VERSION ""

NS_ :

BS_:

BU_: BMS

BO_ 2147528816 SEG_1_MSG: 8 BMS
 SG_ SEG_1_isFaultDetected : 49|1@1+ (1,0) [0|0] "" Vector__XXX
 SG_ SEG_1_isCommsError : 48|1@1+ (1,0) [0|0] "" Vector__XXX
 SG_ SEG_1_IC_Temp : 32|16@1- (0.01,0) [0|0] "degC" Vector__XXX
 SG_ SEG_1_IC_Voltage : 0|32@1- (0.001,0) [0|0] "V" Vector__XXX

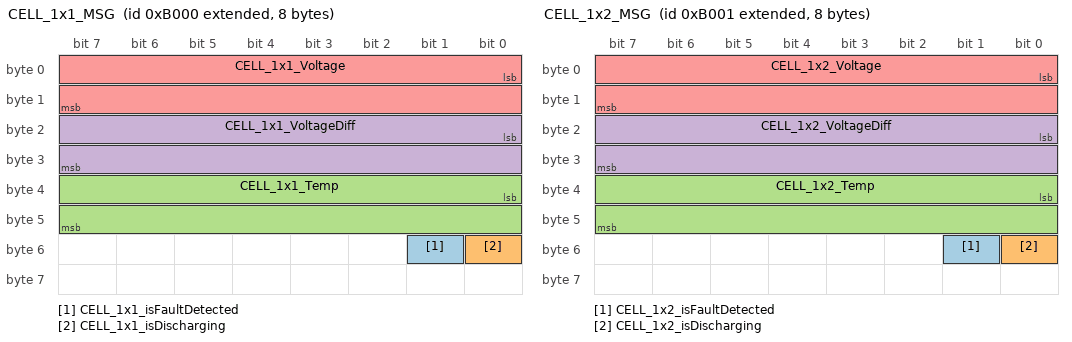
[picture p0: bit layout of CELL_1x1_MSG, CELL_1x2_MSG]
BO_ 2147528704 CELL_1x1_MSG: 8 BMS
 SG_ CELL_1x1_isFaultDetected : 49|1@1+ (1,0) [0|0] "" Vector__XXX
 SG_ CELL_1x1_isDischarging : 48|1@1+ (1,0) [0|0] "" Vector__XXX
 SG_ CELL_1x1_Temp : 32|16@1- (0.01,0) [0|0] "degC" Vector__XXX
 SG_ CELL_1x1_VoltageDiff : 16|16@1- (1,0) [0|0] "mV" Vector__XXX
 SG_ CELL_1x1_Voltage : 0|16@1- (0.001,0) [0|0] "V" Vector__XXX

BO_ 2147528705 CELL_1x2_MSG: 8 BMS
 SG_ CELL_1x2_isFaultDetected : 49|1@1+ (1,0) [0|0] "" Vector__XXX
 SG_ CELL_1x2_isDischarging : 48|1@1+ (1,0) [0|0] "" Vector__XXX
 SG_ CELL_1x2_Temp : 32|16@1- (0.01,0) [0|0] "degC" Vector__XXX
 SG_ CELL_1x2_VoltageDiff : 16|16@1- (1,0) [0|0] "mV" Vector__XXX
 SG_ CELL_1x2_Voltage : 0|16@1- (0.001,0) [0|0] "V" Vector__XXX

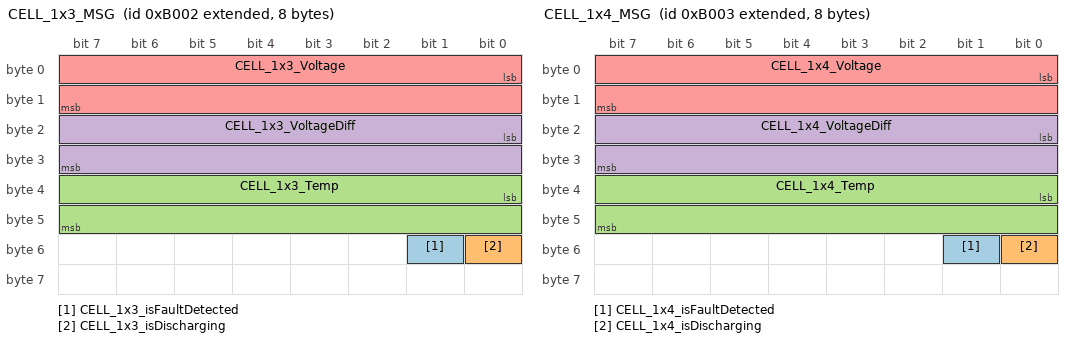
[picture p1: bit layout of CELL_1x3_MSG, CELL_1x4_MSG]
BO_ 2147528706 CELL_1x3_MSG: 8 BMS
 SG_ CELL_1x3_isFaultDetected : 49|1@1+ (1,0) [0|0] "" Vector__XXX
 SG_ CELL_1x3_isDischarging : 48|1@1+ (1,0) [0|0] "" Vector__XXX
 SG_ CELL_1x3_Temp : 32|16@1- (0.01,0) [0|0] "degC" Vector__XXX
 SG_ CELL_1x3_VoltageDiff : 16|16@1- (1,0) [0|0] "mV" Vector__XXX
 SG_ CELL_1x3_Voltage : 0|16@1- (0.001,0) [0|0] "V" Vector__XXX

BO_ 2147528707 CELL_1x4_MSG: 8 BMS
 SG_ CELL_1x4_isFaultDetected : 49|1@1+ (1,0) [0|0] "" Vector__XXX
 SG_ CELL_1x4_isDischarging : 48|1@1+ (1,0) [0|0] "" Vector__XXX
 SG_ CELL_1x4_Temp : 32|16@1- (0.01,0) [0|0] "degC" Vector__XXX
 SG_ CELL_1x4_VoltageDiff : 16|16@1- (1,0) [0|0] "mV" Vector__XXX
 SG_ CELL_1x4_Voltage : 0|16@1- (0.001,0) [0|0] "V" Vector__XXX

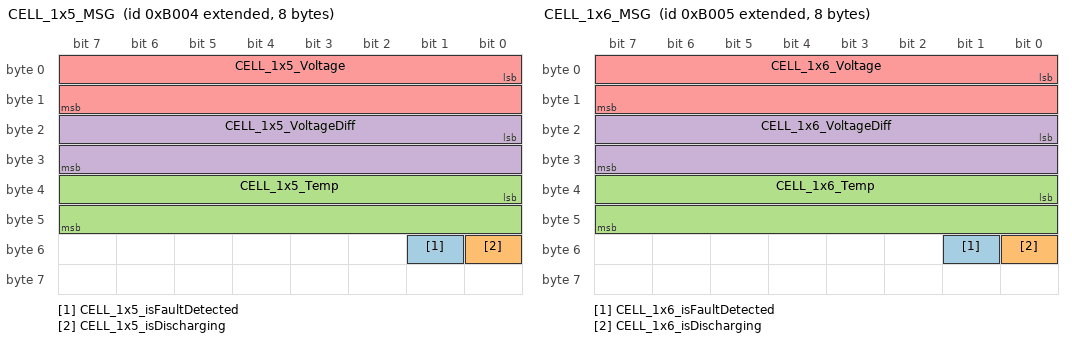
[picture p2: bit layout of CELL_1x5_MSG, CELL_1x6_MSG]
BO_ 2147528708 CELL_1x5_MSG: 8 BMS
 SG_ CELL_1x5_isFaultDetected : 49|1@1+ (1,0) [0|0] "" Vector__XXX
 SG_ CELL_1x5_isDischarging : 48|1@1+ (1,0) [0|0] "" Vector__XXX
 SG_ CELL_1x5_Temp : 32|16@1- (0.01,0) [0|0] "degC" Vector__XXX
 SG_ CELL_1x5_VoltageDiff : 16|16@1- (1,0) [0|0] "mV" Vector__XXX
 SG_ CELL_1x5_Voltage : 0|16@1- (0.001,0) [0|0] "V" Vector__XXX

BO_ 2147528709 CELL_1x6_MSG: 8 BMS
 SG_ CELL_1x6_isFaultDetected : 49|1@1+ (1,0) [0|0] "" Vector__XXX
 SG_ CELL_1x6_isDischarging : 48|1@1+ (1,0) [0|0] "" Vector__XXX
 SG_ CELL_1x6_Temp : 32|16@1- (0.01,0) [0|0] "degC" Vector__XXX
 SG_ CELL_1x6_VoltageDiff : 16|16@1- (1,0) [0|0] "mV" Vector__XXX
 SG_ CELL_1x6_Voltage : 0|16@1- (0.001,0) [0|0] "V" Vector__XXX

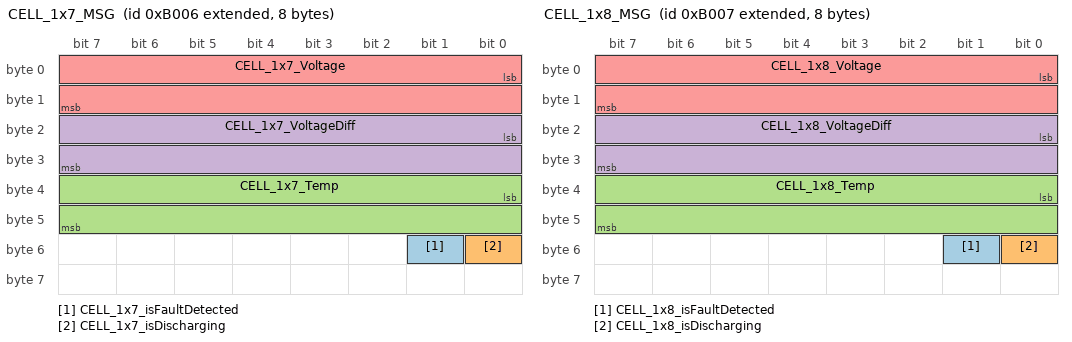
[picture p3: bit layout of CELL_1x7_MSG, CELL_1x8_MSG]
BO_ 2147528710 CELL_1x7_MSG: 8 BMS
 SG_ CELL_1x7_isFaultDetected : 49|1@1+ (1,0) [0|0] "" Vector__XXX
 SG_ CELL_1x7_isDischarging : 48|1@1+ (1,0) [0|0] "" Vector__XXX
 SG_ CELL_1x7_Temp : 32|16@1- (0.01,0) [0|0] "degC" Vector__XXX
 SG_ CELL_1x7_VoltageDiff : 16|16@1- (1,0) [0|0] "mV" Vector__XXX
 SG_ CELL_1x7_Voltage : 0|16@1- (0.001,0) [0|0] "V" Vector__XXX

BO_ 2147528711 CELL_1x8_MSG: 8 BMS
 SG_ CELL_1x8_isFaultDetected : 49|1@1+ (1,0) [0|0] "" Vector__XXX
 SG_ CELL_1x8_isDischarging : 48|1@1+ (1,0) [0|0] "" Vector__XXX
 SG_ CELL_1x8_Temp : 32|16@1- (0.01,0) [0|0] "degC" Vector__XXX
 SG_ CELL_1x8_VoltageDiff : 16|16@1- (1,0) [0|0] "mV" Vector__XXX
 SG_ CELL_1x8_Voltage : 0|16@1- (0.001,0) [0|0] "V" Vector__XXX

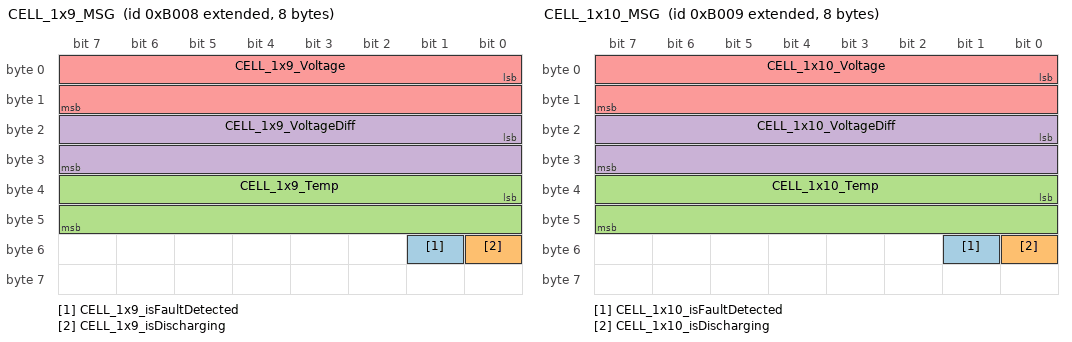
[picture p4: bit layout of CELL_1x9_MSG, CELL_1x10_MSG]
BO_ 2147528712 CELL_1x9_MSG: 8 BMS
 SG_ CELL_1x9_isFaultDetected : 49|1@1+ (1,0) [0|0] "" Vector__XXX
 SG_ CELL_1x9_isDischarging : 48|1@1+ (1,0) [0|0] "" Vector__XXX
 SG_ CELL_1x9_Temp : 32|16@1- (0.01,0) [0|0] "degC" Vector__XXX
 SG_ CELL_1x9_VoltageDiff : 16|16@1- (1,0) [0|0] "mV" Vector__XXX
 SG_ CELL_1x9_Voltage : 0|16@1- (0.001,0) [0|0] "V" Vector__XXX

BO_ 2147528713 CELL_1x10_MSG: 8 BMS
 SG_ CELL_1x10_isFaultDetected : 49|1@1+ (1,0) [0|0] "" Vector__XXX
 SG_ CELL_1x10_isDischarging : 48|1@1+ (1,0) [0|0] "" Vector__XXX
 SG_ CELL_1x10_Temp : 32|16@1- (0.01,0) [0|0] "degC" Vector__XXX
 SG_ CELL_1x10_VoltageDiff : 16|16@1- (1,0) [0|0] "mV" Vector__XXX
 SG_ CELL_1x10_Voltage : 0|16@1- (0.001,0) [0|0] "V" Vector__XXX

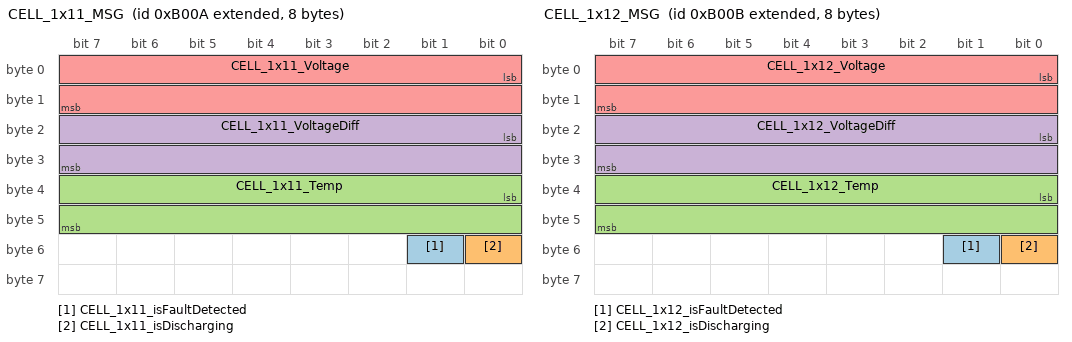
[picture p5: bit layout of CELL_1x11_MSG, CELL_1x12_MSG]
BO_ 2147528714 CELL_1x11_MSG: 8 BMS
 SG_ CELL_1x11_isFaultDetected : 49|1@1+ (1,0) [0|0] "" Vector__XXX
 SG_ CELL_1x11_isDischarging : 48|1@1+ (1,0) [0|0] "" Vector__XXX
 SG_ CELL_1x11_Temp : 32|16@1- (0.01,0) [0|0] "degC" Vector__XXX
 SG_ CELL_1x11_VoltageDiff : 16|16@1- (1,0) [0|0] "mV" Vector__XXX
 SG_ CELL_1x11_Voltage : 0|16@1- (0.001,0) [0|0] "V" Vector__XXX

BO_ 2147528715 CELL_1x12_MSG: 8 BMS
 SG_ CELL_1x12_isFaultDetected : 49|1@1+ (1,0) [0|0] "" Vector__XXX
 SG_ CELL_1x12_isDischarging : 48|1@1+ (1,0) [0|0] "" Vector__XXX
 SG_ CELL_1x12_Temp : 32|16@1- (0.01,0) [0|0] "degC" Vector__XXX
 SG_ CELL_1x12_VoltageDiff : 16|16@1- (1,0) [0|0] "mV" Vector__XXX
 SG_ CELL_1x12_Voltage : 0|16@1- (0.001,0) [0|0] "V" Vector__XXX

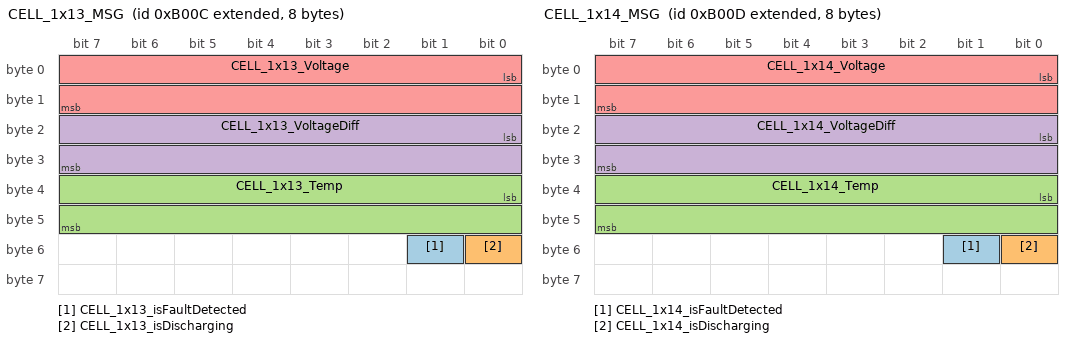
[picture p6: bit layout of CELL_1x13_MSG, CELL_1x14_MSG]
BO_ 2147528716 CELL_1x13_MSG: 8 BMS
 SG_ CELL_1x13_isFaultDetected : 49|1@1+ (1,0) [0|0] "" Vector__XXX
 SG_ CELL_1x13_isDischarging : 48|1@1+ (1,0) [0|0] "" Vector__XXX
 SG_ CELL_1x13_Temp : 32|16@1- (0.01,0) [0|0] "degC" Vector__XXX
 SG_ CELL_1x13_VoltageDiff : 16|16@1- (1,0) [0|0] "mV" Vector__XXX
 SG_ CELL_1x13_Voltage : 0|16@1- (0.001,0) [0|0] "V" Vector__XXX

BO_ 2147528717 CELL_1x14_MSG: 8 BMS
 SG_ CELL_1x14_isFaultDetected : 49|1@1+ (1,0) [0|0] "" Vector__XXX
 SG_ CELL_1x14_isDischarging : 48|1@1+ (1,0) [0|0] "" Vector__XXX
 SG_ CELL_1x14_Temp : 32|16@1- (0.01,0) [0|0] "degC" Vector__XXX
 SG_ CELL_1x14_VoltageDiff : 16|16@1- (1,0) [0|0] "mV" Vector__XXX
 SG_ CELL_1x14_Voltage : 0|16@1- (0.001,0) [0|0] "V" Vector__XXX

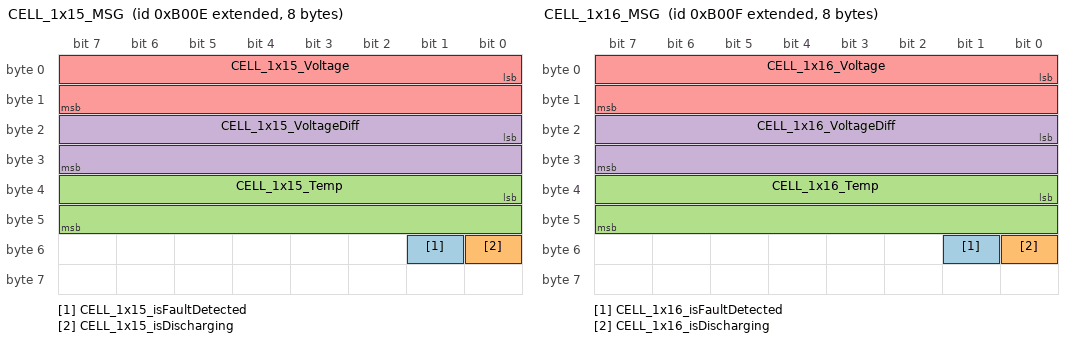
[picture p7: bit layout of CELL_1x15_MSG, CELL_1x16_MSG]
BO_ 2147528718 CELL_1x15_MSG: 8 BMS
 SG_ CELL_1x15_isFaultDetected : 49|1@1+ (1,0) [0|0] "" Vector__XXX
 SG_ CELL_1x15_isDischarging : 48|1@1+ (1,0) [0|0] "" Vector__XXX
 SG_ CELL_1x15_Temp : 32|16@1- (0.01,0) [0|0] "degC" Vector__XXX
 SG_ CELL_1x15_VoltageDiff : 16|16@1- (1,0) [0|0] "mV" Vector__XXX
 SG_ CELL_1x15_Voltage : 0|16@1- (0.001,0) [0|0] "V" Vector__XXX

BO_ 2147528719 CELL_1x16_MSG: 8 BMS
 SG_ CELL_1x16_isFaultDetected : 49|1@1+ (1,0) [0|0] "" Vector__XXX
 SG_ CELL_1x16_isDischarging : 48|1@1+ (1,0) [0|0] "" Vector__XXX
 SG_ CELL_1x16_Temp : 32|16@1- (0.01,0) [0|0] "degC" Vector__XXX
 SG_ CELL_1x16_VoltageDiff : 16|16@1- (1,0) [0|0] "mV" Vector__XXX
 SG_ CELL_1x16_Voltage : 0|16@1- (0.001,0) [0|0] "V" Vector__XXX

BO_ 2147528817 SEG_2_MSG: 8 BMS
 SG_ SEG_2_isFaultDetected : 49|1@1+ (1,0) [0|0] "" Vector__XXX
 SG_ SEG_2_isCommsError : 48|1@1+ (1,0) [0|0] "" Vector__XXX
 SG_ SEG_2_IC_Temp : 32|16@1- (0.01,0) [0|0] "degC" Vector__XXX
 SG_ SEG_2_IC_Voltage : 0|32@1- (0.001,0) [0|0] "V" Vector__XXX

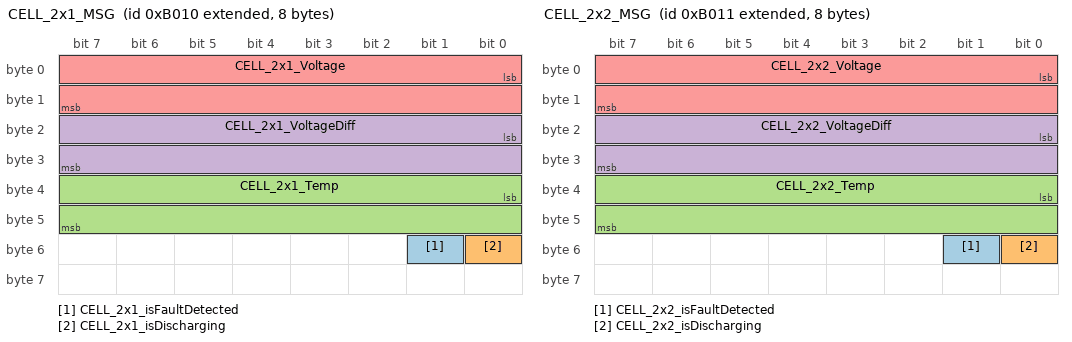
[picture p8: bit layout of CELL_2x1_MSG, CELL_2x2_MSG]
BO_ 2147528720 CELL_2x1_MSG: 8 BMS
 SG_ CELL_2x1_isFaultDetected : 49|1@1+ (1,0) [0|0] "" Vector__XXX
 SG_ CELL_2x1_isDischarging : 48|1@1+ (1,0) [0|0] "" Vector__XXX
 SG_ CELL_2x1_Temp : 32|16@1- (0.01,0) [0|0] "degC" Vector__XXX
 SG_ CELL_2x1_VoltageDiff : 16|16@1- (1,0) [0|0] "mV" Vector__XXX
 SG_ CELL_2x1_Voltage : 0|16@1- (0.001,0) [0|0] "V" Vector__XXX

BO_ 2147528721 CELL_2x2_MSG: 8 BMS
 SG_ CELL_2x2_isFaultDetected : 49|1@1+ (1,0) [0|0] "" Vector__XXX
 SG_ CELL_2x2_isDischarging : 48|1@1+ (1,0) [0|0] "" Vector__XXX
 SG_ CELL_2x2_Temp : 32|16@1- (0.01,0) [0|0] "degC" Vector__XXX
 SG_ CELL_2x2_VoltageDiff : 16|16@1- (1,0) [0|0] "mV" Vector__XXX
 SG_ CELL_2x2_Voltage : 0|16@1- (0.001,0) [0|0] "V" Vector__XXX

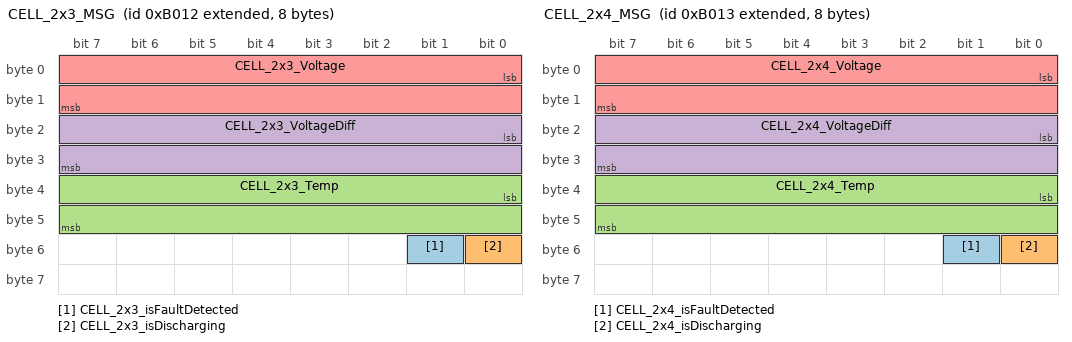
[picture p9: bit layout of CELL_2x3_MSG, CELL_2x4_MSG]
BO_ 2147528722 CELL_2x3_MSG: 8 BMS
 SG_ CELL_2x3_isFaultDetected : 49|1@1+ (1,0) [0|0] "" Vector__XXX
 SG_ CELL_2x3_isDischarging : 48|1@1+ (1,0) [0|0] "" Vector__XXX
 SG_ CELL_2x3_Temp : 32|16@1- (0.01,0) [0|0] "degC" Vector__XXX
 SG_ CELL_2x3_VoltageDiff : 16|16@1- (1,0) [0|0] "mV" Vector__XXX
 SG_ CELL_2x3_Voltage : 0|16@1- (0.001,0) [0|0] "V" Vector__XXX

BO_ 2147528723 CELL_2x4_MSG: 8 BMS
 SG_ CELL_2x4_isFaultDetected : 49|1@1+ (1,0) [0|0] "" Vector__XXX
 SG_ CELL_2x4_isDischarging : 48|1@1+ (1,0) [0|0] "" Vector__XXX
 SG_ CELL_2x4_Temp : 32|16@1- (0.01,0) [0|0] "degC" Vector__XXX
 SG_ CELL_2x4_VoltageDiff : 16|16@1- (1,0) [0|0] "mV" Vector__XXX
 SG_ CELL_2x4_Voltage : 0|16@1- (0.001,0) [0|0] "V" Vector__XXX

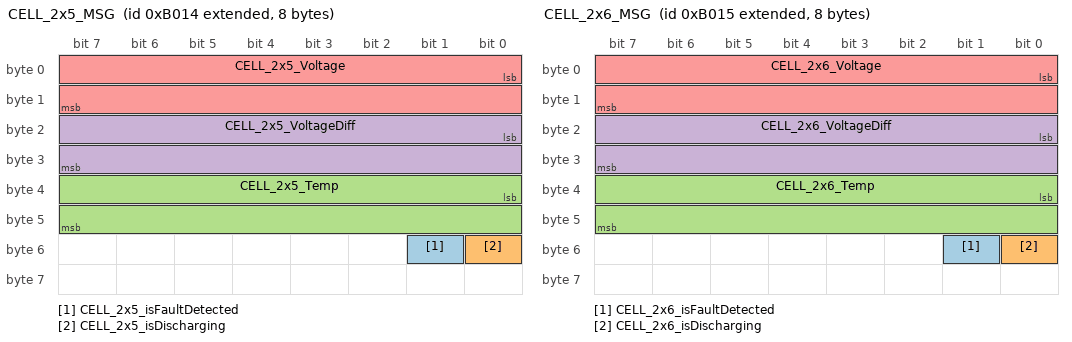
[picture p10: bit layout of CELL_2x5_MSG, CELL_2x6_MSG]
BO_ 2147528724 CELL_2x5_MSG: 8 BMS
 SG_ CELL_2x5_isFaultDetected : 49|1@1+ (1,0) [0|0] "" Vector__XXX
 SG_ CELL_2x5_isDischarging : 48|1@1+ (1,0) [0|0] "" Vector__XXX
 SG_ CELL_2x5_Temp : 32|16@1- (0.01,0) [0|0] "degC" Vector__XXX
 SG_ CELL_2x5_VoltageDiff : 16|16@1- (1,0) [0|0] "mV" Vector__XXX
 SG_ CELL_2x5_Voltage : 0|16@1- (0.001,0) [0|0] "V" Vector__XXX

BO_ 2147528725 CELL_2x6_MSG: 8 BMS
 SG_ CELL_2x6_isFaultDetected : 49|1@1+ (1,0) [0|0] "" Vector__XXX
 SG_ CELL_2x6_isDischarging : 48|1@1+ (1,0) [0|0] "" Vector__XXX
 SG_ CELL_2x6_Temp : 32|16@1- (0.01,0) [0|0] "degC" Vector__XXX
 SG_ CELL_2x6_VoltageDiff : 16|16@1- (1,0) [0|0] "mV" Vector__XXX
 SG_ CELL_2x6_Voltage : 0|16@1- (0.001,0) [0|0] "V" Vector__XXX

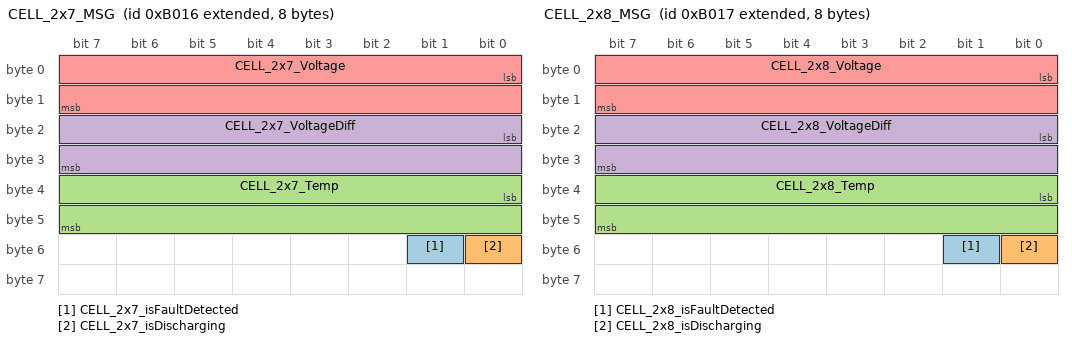
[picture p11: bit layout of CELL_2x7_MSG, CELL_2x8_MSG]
BO_ 2147528726 CELL_2x7_MSG: 8 BMS
 SG_ CELL_2x7_isFaultDetected : 49|1@1+ (1,0) [0|0] "" Vector__XXX
 SG_ CELL_2x7_isDischarging : 48|1@1+ (1,0) [0|0] "" Vector__XXX
 SG_ CELL_2x7_Temp : 32|16@1- (0.01,0) [0|0] "degC" Vector__XXX
 SG_ CELL_2x7_VoltageDiff : 16|16@1- (1,0) [0|0] "mV" Vector__XXX
 SG_ CELL_2x7_Voltage : 0|16@1- (0.001,0) [0|0] "V" Vector__XXX

BO_ 2147528727 CELL_2x8_MSG: 8 BMS
 SG_ CELL_2x8_isFaultDetected : 49|1@1+ (1,0) [0|0] "" Vector__XXX
 SG_ CELL_2x8_isDischarging : 48|1@1+ (1,0) [0|0] "" Vector__XXX
 SG_ CELL_2x8_Temp : 32|16@1- (0.01,0) [0|0] "degC" Vector__XXX
 SG_ CELL_2x8_VoltageDiff : 16|16@1- (1,0) [0|0] "mV" Vector__XXX
 SG_ CELL_2x8_Voltage : 0|16@1- (0.001,0) [0|0] "V" Vector__XXX

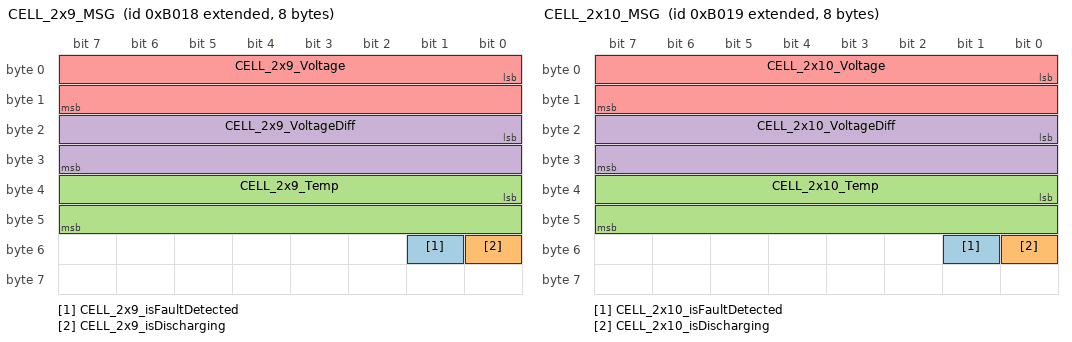
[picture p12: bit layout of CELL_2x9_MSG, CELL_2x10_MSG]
BO_ 2147528728 CELL_2x9_MSG: 8 BMS
 SG_ CELL_2x9_isFaultDetected : 49|1@1+ (1,0) [0|0] "" Vector__XXX
 SG_ CELL_2x9_isDischarging : 48|1@1+ (1,0) [0|0] "" Vector__XXX
 SG_ CELL_2x9_Temp : 32|16@1- (0.01,0) [0|0] "degC" Vector__XXX
 SG_ CELL_2x9_VoltageDiff : 16|16@1- (1,0) [0|0] "mV" Vector__XXX
 SG_ CELL_2x9_Voltage : 0|16@1- (0.001,0) [0|0] "V" Vector__XXX

BO_ 2147528729 CELL_2x10_MSG: 8 BMS
 SG_ CELL_2x10_isFaultDetected : 49|1@1+ (1,0) [0|0] "" Vector__XXX
 SG_ CELL_2x10_isDischarging : 48|1@1+ (1,0) [0|0] "" Vector__XXX
 SG_ CELL_2x10_Temp : 32|16@1- (0.01,0) [0|0] "degC" Vector__XXX
 SG_ CELL_2x10_VoltageDiff : 16|16@1- (1,0) [0|0] "mV" Vector__XXX
 SG_ CELL_2x10_Voltage : 0|16@1- (0.001,0) [0|0] "V" Vector__XXX

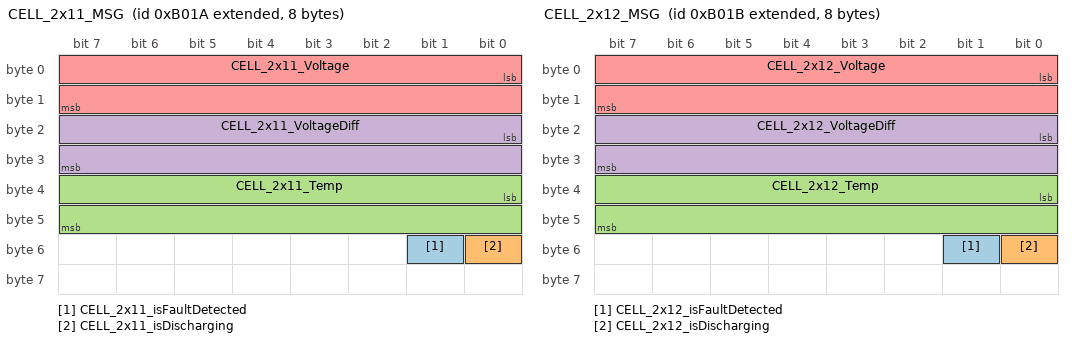
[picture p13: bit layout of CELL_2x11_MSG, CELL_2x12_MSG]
BO_ 2147528730 CELL_2x11_MSG: 8 BMS
 SG_ CELL_2x11_isFaultDetected : 49|1@1+ (1,0) [0|0] "" Vector__XXX
 SG_ CELL_2x11_isDischarging : 48|1@1+ (1,0) [0|0] "" Vector__XXX
 SG_ CELL_2x11_Temp : 32|16@1- (0.01,0) [0|0] "degC" Vector__XXX
 SG_ CELL_2x11_VoltageDiff : 16|16@1- (1,0) [0|0] "mV" Vector__XXX
 SG_ CELL_2x11_Voltage : 0|16@1- (0.001,0) [0|0] "V" Vector__XXX

BO_ 2147528731 CELL_2x12_MSG: 8 BMS
 SG_ CELL_2x12_isFaultDetected : 49|1@1+ (1,0) [0|0] "" Vector__XXX
 SG_ CELL_2x12_isDischarging : 48|1@1+ (1,0) [0|0] "" Vector__XXX
 SG_ CELL_2x12_Temp : 32|16@1- (0.01,0) [0|0] "degC" Vector__XXX
 SG_ CELL_2x12_VoltageDiff : 16|16@1- (1,0) [0|0] "mV" Vector__XXX
 SG_ CELL_2x12_Voltage : 0|16@1- (0.001,0) [0|0] "V" Vector__XXX

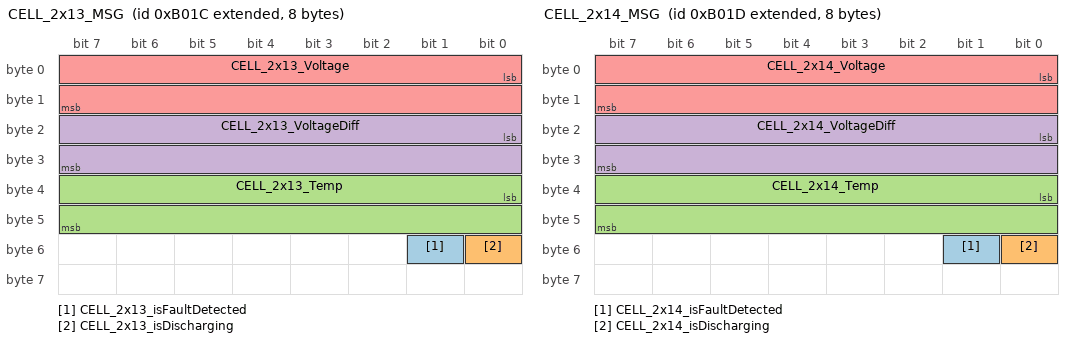
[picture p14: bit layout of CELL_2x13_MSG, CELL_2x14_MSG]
BO_ 2147528732 CELL_2x13_MSG: 8 BMS
 SG_ CELL_2x13_isFaultDetected : 49|1@1+ (1,0) [0|0] "" Vector__XXX
 SG_ CELL_2x13_isDischarging : 48|1@1+ (1,0) [0|0] "" Vector__XXX
 SG_ CELL_2x13_Temp : 32|16@1- (0.01,0) [0|0] "degC" Vector__XXX
 SG_ CELL_2x13_VoltageDiff : 16|16@1- (1,0) [0|0] "mV" Vector__XXX
 SG_ CELL_2x13_Voltage : 0|16@1- (0.001,0) [0|0] "V" Vector__XXX

BO_ 2147528733 CELL_2x14_MSG: 8 BMS
 SG_ CELL_2x14_isFaultDetected : 49|1@1+ (1,0) [0|0] "" Vector__XXX
 SG_ CELL_2x14_isDischarging : 48|1@1+ (1,0) [0|0] "" Vector__XXX
 SG_ CELL_2x14_Temp : 32|16@1- (0.01,0) [0|0] "degC" Vector__XXX
 SG_ CELL_2x14_VoltageDiff : 16|16@1- (1,0) [0|0] "mV" Vector__XXX
 SG_ CELL_2x14_Voltage : 0|16@1- (0.001,0) [0|0] "V" Vector__XXX

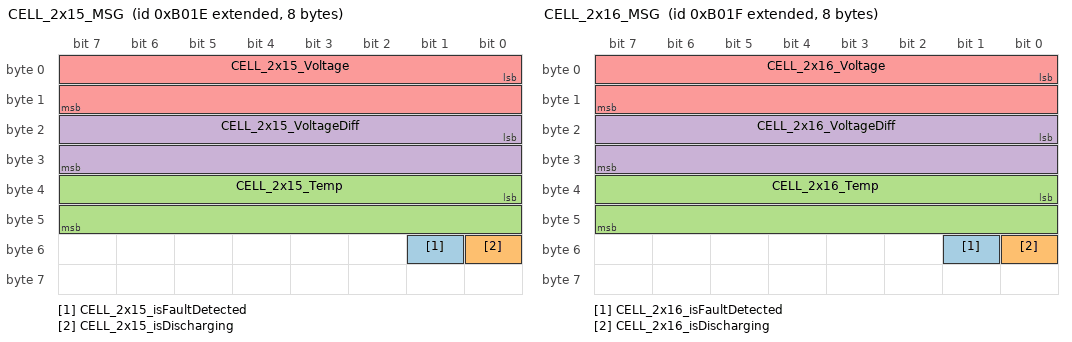
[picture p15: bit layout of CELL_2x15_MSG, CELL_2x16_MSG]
BO_ 2147528734 CELL_2x15_MSG: 8 BMS
 SG_ CELL_2x15_isFaultDetected : 49|1@1+ (1,0) [0|0] "" Vector__XXX
 SG_ CELL_2x15_isDischarging : 48|1@1+ (1,0) [0|0] "" Vector__XXX
 SG_ CELL_2x15_Temp : 32|16@1- (0.01,0) [0|0] "degC" Vector__XXX
 SG_ CELL_2x15_VoltageDiff : 16|16@1- (1,0) [0|0] "mV" Vector__XXX
 SG_ CELL_2x15_Voltage : 0|16@1- (0.001,0) [0|0] "V" Vector__XXX

BO_ 2147528735 CELL_2x16_MSG: 8 BMS
 SG_ CELL_2x16_isFaultDetected : 49|1@1+ (1,0) [0|0] "" Vector__XXX
 SG_ CELL_2x16_isDischarging : 48|1@1+ (1,0) [0|0] "" Vector__XXX
 SG_ CELL_2x16_Temp : 32|16@1- (0.01,0) [0|0] "degC" Vector__XXX
 SG_ CELL_2x16_VoltageDiff : 16|16@1- (1,0) [0|0] "mV" Vector__XXX
 SG_ CELL_2x16_Voltage : 0|16@1- (0.001,0) [0|0] "V" Vector__XXX

BO_ 2147528818 SEG_3_MSG: 8 BMS
 SG_ SEG_3_isFaultDetected : 49|1@1+ (1,0) [0|0] "" Vector__XXX
 SG_ SEG_3_isCommsError : 48|1@1+ (1,0) [0|0] "" Vector__XXX
 SG_ SEG_3_IC_Temp : 32|16@1- (0.01,0) [0|0] "degC" Vector__XXX
 SG_ SEG_3_IC_Voltage : 0|32@1- (0.001,0) [0|0] "V" Vector__XXX

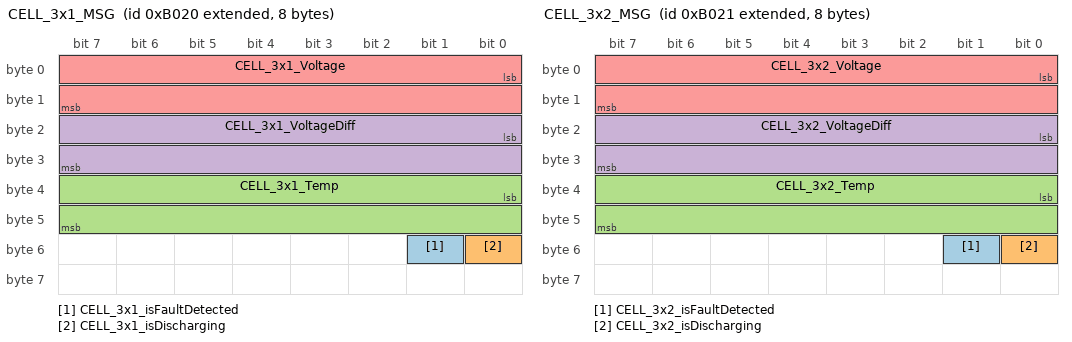
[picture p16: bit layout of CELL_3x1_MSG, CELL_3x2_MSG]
BO_ 2147528736 CELL_3x1_MSG: 8 BMS
 SG_ CELL_3x1_isFaultDetected : 49|1@1+ (1,0) [0|0] "" Vector__XXX
 SG_ CELL_3x1_isDischarging : 48|1@1+ (1,0) [0|0] "" Vector__XXX
 SG_ CELL_3x1_Temp : 32|16@1- (0.01,0) [0|0] "degC" Vector__XXX
 SG_ CELL_3x1_VoltageDiff : 16|16@1- (1,0) [0|0] "mV" Vector__XXX
 SG_ CELL_3x1_Voltage : 0|16@1- (0.001,0) [0|0] "V" Vector__XXX

BO_ 2147528737 CELL_3x2_MSG: 8 BMS
 SG_ CELL_3x2_isFaultDetected : 49|1@1+ (1,0) [0|0] "" Vector__XXX
 SG_ CELL_3x2_isDischarging : 48|1@1+ (1,0) [0|0] "" Vector__XXX
 SG_ CELL_3x2_Temp : 32|16@1- (0.01,0) [0|0] "degC" Vector__XXX
 SG_ CELL_3x2_VoltageDiff : 16|16@1- (1,0) [0|0] "mV" Vector__XXX
 SG_ CELL_3x2_Voltage : 0|16@1- (0.001,0) [0|0] "V" Vector__XXX

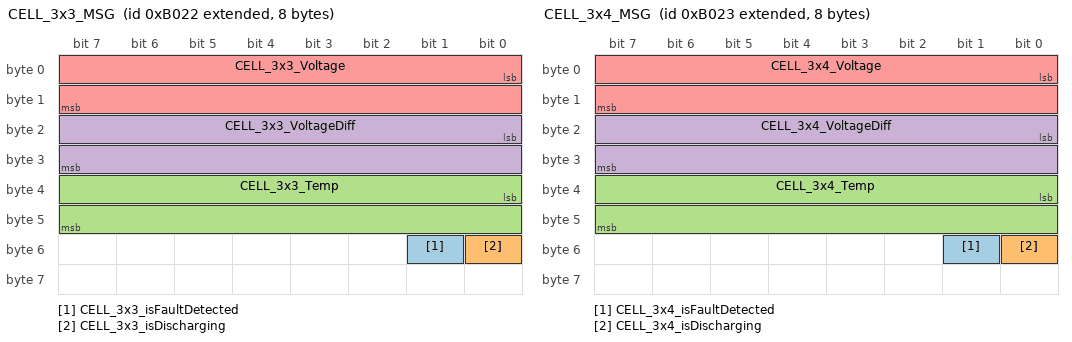
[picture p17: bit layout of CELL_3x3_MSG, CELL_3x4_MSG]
BO_ 2147528738 CELL_3x3_MSG: 8 BMS
 SG_ CELL_3x3_isFaultDetected : 49|1@1+ (1,0) [0|0] "" Vector__XXX
 SG_ CELL_3x3_isDischarging : 48|1@1+ (1,0) [0|0] "" Vector__XXX
 SG_ CELL_3x3_Temp : 32|16@1- (0.01,0) [0|0] "degC" Vector__XXX
 SG_ CELL_3x3_VoltageDiff : 16|16@1- (1,0) [0|0] "mV" Vector__XXX
 SG_ CELL_3x3_Voltage : 0|16@1- (0.001,0) [0|0] "V" Vector__XXX

BO_ 2147528739 CELL_3x4_MSG: 8 BMS
 SG_ CELL_3x4_isFaultDetected : 49|1@1+ (1,0) [0|0] "" Vector__XXX
 SG_ CELL_3x4_isDischarging : 48|1@1+ (1,0) [0|0] "" Vector__XXX
 SG_ CELL_3x4_Temp : 32|16@1- (0.01,0) [0|0] "degC" Vector__XXX
 SG_ CELL_3x4_VoltageDiff : 16|16@1- (1,0) [0|0] "mV" Vector__XXX
 SG_ CELL_3x4_Voltage : 0|16@1- (0.001,0) [0|0] "V" Vector__XXX

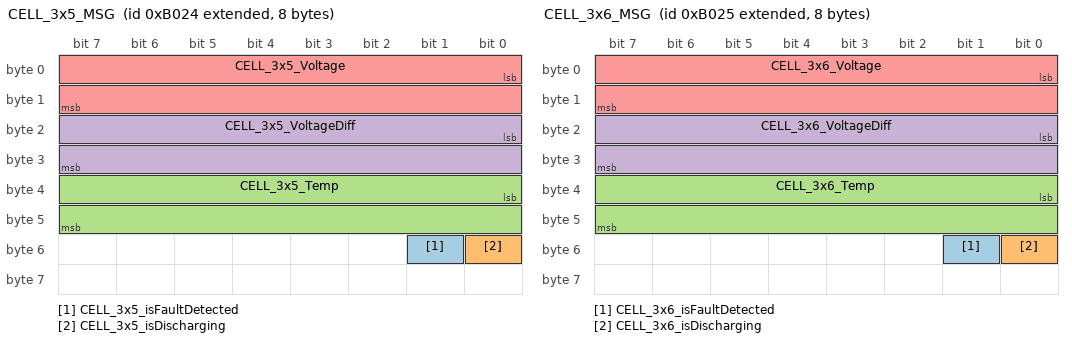
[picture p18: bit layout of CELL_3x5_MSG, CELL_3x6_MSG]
BO_ 2147528740 CELL_3x5_MSG: 8 BMS
 SG_ CELL_3x5_isFaultDetected : 49|1@1+ (1,0) [0|0] "" Vector__XXX
 SG_ CELL_3x5_isDischarging : 48|1@1+ (1,0) [0|0] "" Vector__XXX
 SG_ CELL_3x5_Temp : 32|16@1- (0.01,0) [0|0] "degC" Vector__XXX
 SG_ CELL_3x5_VoltageDiff : 16|16@1- (1,0) [0|0] "mV" Vector__XXX
 SG_ CELL_3x5_Voltage : 0|16@1- (0.001,0) [0|0] "V" Vector__XXX

BO_ 2147528741 CELL_3x6_MSG: 8 BMS
 SG_ CELL_3x6_isFaultDetected : 49|1@1+ (1,0) [0|0] "" Vector__XXX
 SG_ CELL_3x6_isDischarging : 48|1@1+ (1,0) [0|0] "" Vector__XXX
 SG_ CELL_3x6_Temp : 32|16@1- (0.01,0) [0|0] "degC" Vector__XXX
 SG_ CELL_3x6_VoltageDiff : 16|16@1- (1,0) [0|0] "mV" Vector__XXX
 SG_ CELL_3x6_Voltage : 0|16@1- (0.001,0) [0|0] "V" Vector__XXX

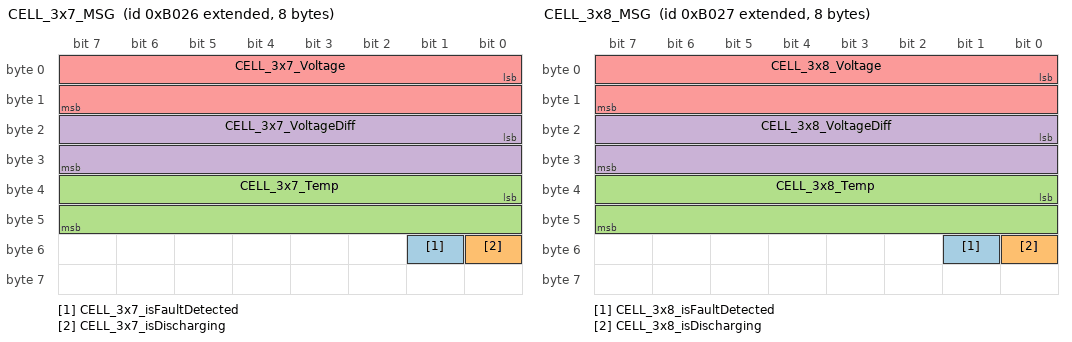
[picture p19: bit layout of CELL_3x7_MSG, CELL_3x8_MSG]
BO_ 2147528742 CELL_3x7_MSG: 8 BMS
 SG_ CELL_3x7_isFaultDetected : 49|1@1+ (1,0) [0|0] "" Vector__XXX
 SG_ CELL_3x7_isDischarging : 48|1@1+ (1,0) [0|0] "" Vector__XXX
 SG_ CELL_3x7_Temp : 32|16@1- (0.01,0) [0|0] "degC" Vector__XXX
 SG_ CELL_3x7_VoltageDiff : 16|16@1- (1,0) [0|0] "mV" Vector__XXX
 SG_ CELL_3x7_Voltage : 0|16@1- (0.001,0) [0|0] "V" Vector__XXX

BO_ 2147528743 CELL_3x8_MSG: 8 BMS
 SG_ CELL_3x8_isFaultDetected : 49|1@1+ (1,0) [0|0] "" Vector__XXX
 SG_ CELL_3x8_isDischarging : 48|1@1+ (1,0) [0|0] "" Vector__XXX
 SG_ CELL_3x8_Temp : 32|16@1- (0.01,0) [0|0] "degC" Vector__XXX
 SG_ CELL_3x8_VoltageDiff : 16|16@1- (1,0) [0|0] "mV" Vector__XXX
 SG_ CELL_3x8_Voltage : 0|16@1- (0.001,0) [0|0] "V" Vector__XXX

BO_ 2147528744 CELL_3x9_MSG: 8 BMS
 SG_ CELL_3x9_isFaultDetected : 49|1@1+ (1,0) [0|0] "" Vector__XXX
 SG_ CELL_3x9_isDischarging : 48|1@1+ (1,0) [0|0] "" Vector__XXX
 SG_ CELL_3x9_Temp : 32|16@1- (0.01,0) [0|0] "degC" Vector__XXX
 SG_ CELL_3x9_VoltageDiff : 16|16@1- (1,0) [0|0] "mV" Vector__XXX
 SG_ CELL_3x9_Voltage : 0|16@1- (0.001,0) [0|0] "V" Vector__XXX

BO_ 2147528745 CELL_3x10_MSG: 8 BMS
 SG_ CELL_3x10_isFaultDetected : 49|1@1+ (1,0) [0|0] "" Vector__XXX
 SG_ CELL_3x10_isDischarging : 48|1@1+ (1,0) [0|0] "" Vector__XXX
 SG_ CELL_3x10_Temp : 32|16@1- (0.01,0) [0|0] "degC" Vector__XXX
 SG_ CELL_3x10_VoltageDiff : 16|16@1- (1,0) [0|0] "mV" Vector__XXX
 SG_ CELL_3x10_Voltage : 0|16@1- (0.001,0) [0|0] "V" Vector__XXX

BO_ 2147528746 CELL_3x11_MSG: 8 BMS
 SG_ CELL_3x11_isFaultDetected : 49|1@1+ (1,0) [0|0] "" Vector__XXX
 SG_ CELL_3x11_isDischarging : 48|1@1+ (1,0) [0|0] "" Vector__XXX
 SG_ CELL_3x11_Temp : 32|16@1- (0.01,0) [0|0] "degC" Vector__XXX
 SG_ CELL_3x11_VoltageDiff : 16|16@1- (1,0) [0|0] "mV" Vector__XXX
 SG_ CELL_3x11_Voltage : 0|16@1- (0.001,0) [0|0] "V" Vector__XXX

BO_ 2147528747 CELL_3x12_MSG: 8 BMS
 SG_ CELL_3x12_isFaultDetected : 49|1@1+ (1,0) [0|0] "" Vector__XXX
 SG_ CELL_3x12_isDischarging : 48|1@1+ (1,0) [0|0] "" Vector__XXX
 SG_ CELL_3x12_Temp : 32|16@1- (0.01,0) [0|0] "degC" Vector__XXX
 SG_ CELL_3x12_VoltageDiff : 16|16@1- (1,0) [0|0] "mV" Vector__XXX
 SG_ CELL_3x12_Voltage : 0|16@1- (0.001,0) [0|0] "V" Vector__XXX

BO_ 2147528748 CELL_3x13_MSG: 8 BMS
 SG_ CELL_3x13_isFaultDetected : 49|1@1+ (1,0) [0|0] "" Vector__XXX
 SG_ CELL_3x13_isDischarging : 48|1@1+ (1,0) [0|0] "" Vector__XXX
 SG_ CELL_3x13_Temp : 32|16@1- (0.01,0) [0|0] "degC" Vector__XXX
 SG_ CELL_3x13_VoltageDiff : 16|16@1- (1,0) [0|0] "mV" Vector__XXX
 SG_ CELL_3x13_Voltage : 0|16@1- (0.001,0) [0|0] "V" Vector__XXX

BO_ 2147528749 CELL_3x14_MSG: 8 BMS
 SG_ CELL_3x14_isFaultDetected : 49|1@1+ (1,0) [0|0] "" Vector__XXX
 SG_ CELL_3x14_isDischarging : 48|1@1+ (1,0) [0|0] "" Vector__XXX
 SG_ CELL_3x14_Temp : 32|16@1- (0.01,0) [0|0] "degC" Vector__XXX
 SG_ CELL_3x14_VoltageDiff : 16|16@1- (1,0) [0|0] "mV" Vector__XXX
 SG_ CELL_3x14_Voltage : 0|16@1- (0.001,0) [0|0] "V" Vector__XXX

BO_ 2147528750 CELL_3x15_MSG: 8 BMS
 SG_ CELL_3x15_isFaultDetected : 49|1@1+ (1,0) [0|0] "" Vector__XXX
 SG_ CELL_3x15_isDischarging : 48|1@1+ (1,0) [0|0] "" Vector__XXX
 SG_ CELL_3x15_Temp : 32|16@1- (0.01,0) [0|0] "degC" Vector__XXX
 SG_ CELL_3x15_VoltageDiff : 16|16@1- (1,0) [0|0] "mV" Vector__XXX
 SG_ CELL_3x15_Voltage : 0|16@1- (0.001,0) [0|0] "V" Vector__XXX

BO_ 2147528751 CELL_3x16_MSG: 8 BMS
 SG_ CELL_3x16_isFaultDetected : 49|1@1+ (1,0) [0|0] "" Vector__XXX
 SG_ CELL_3x16_isDischarging : 48|1@1+ (1,0) [0|0] "" Vector__XXX
 SG_ CELL_3x16_Temp : 32|16@1- (0.01,0) [0|0] "degC" Vector__XXX
 SG_ CELL_3x16_VoltageDiff : 16|16@1- (1,0) [0|0] "mV" Vector__XXX
 SG_ CELL_3x16_Voltage : 0|16@1- (0.001,0) [0|0] "V" Vector__XXX

BO_ 2147528819 SEG_4_MSG: 8 BMS
 SG_ SEG_4_isFaultDetected : 49|1@1+ (1,0) [0|0] "" Vector__XXX
 SG_ SEG_4_isCommsError : 48|1@1+ (1,0) [0|0] "" Vector__XXX
 SG_ SEG_4_IC_Temp : 32|16@1- (0.01,0) [0|0] "degC" Vector__XXX
 SG_ SEG_4_IC_Voltage : 0|32@1- (0.001,0) [0|0] "V" Vector__XXX

BO_ 2147528752 CELL_4x1_MSG: 8 BMS
 SG_ CELL_4x1_isFaultDetected : 49|1@1+ (1,0) [0|0] "" Vector__XXX
 SG_ CELL_4x1_isDischarging : 48|1@1+ (1,0) [0|0] "" Vector__XXX
 SG_ CELL_4x1_Temp : 32|16@1- (0.01,0) [0|0] "degC" Vector__XXX
 SG_ CELL_4x1_VoltageDiff : 16|16@1- (1,0) [0|0] "mV" Vector__XXX
 SG_ CELL_4x1_Voltage : 0|16@1- (0.001,0) [0|0] "V" Vector__XXX

BO_ 2147528753 CELL_4x2_MSG: 8 BMS
 SG_ CELL_4x2_isFaultDetected : 49|1@1+ (1,0) [0|0] "" Vector__XXX
 SG_ CELL_4x2_isDischarging : 48|1@1+ (1,0) [0|0] "" Vector__XXX
 SG_ CELL_4x2_Temp : 32|16@1- (0.01,0) [0|0] "degC" Vector__XXX
 SG_ CELL_4x2_VoltageDiff : 16|16@1- (1,0) [0|0] "mV" Vector__XXX
 SG_ CELL_4x2_Voltage : 0|16@1- (0.001,0) [0|0] "V" Vector__XXX

BO_ 2147528754 CELL_4x3_MSG: 8 BMS
 SG_ CELL_4x3_isFaultDetected : 49|1@1+ (1,0) [0|0] "" Vector__XXX
 SG_ CELL_4x3_isDischarging : 48|1@1+ (1,0) [0|0] "" Vector__XXX
 SG_ CELL_4x3_Temp : 32|16@1- (0.01,0) [0|0] "degC" Vector__XXX
 SG_ CELL_4x3_VoltageDiff : 16|16@1- (1,0) [0|0] "mV" Vector__XXX
 SG_ CELL_4x3_Voltage : 0|16@1- (0.001,0) [0|0] "V" Vector__XXX

BO_ 2147528755 CELL_4x4_MSG: 8 BMS
 SG_ CELL_4x4_isFaultDetected : 49|1@1+ (1,0) [0|0] "" Vector__XXX
 SG_ CELL_4x4_isDischarging : 48|1@1+ (1,0) [0|0] "" Vector__XXX
 SG_ CELL_4x4_Temp : 32|16@1- (0.01,0) [0|0] "degC" Vector__XXX
 SG_ CELL_4x4_VoltageDiff : 16|16@1- (1,0) [0|0] "mV" Vector__XXX
 SG_ CELL_4x4_Voltage : 0|16@1- (0.001,0) [0|0] "V" Vector__XXX

BO_ 2147528756 CELL_4x5_MSG: 8 BMS
 SG_ CELL_4x5_isFaultDetected : 49|1@1+ (1,0) [0|0] "" Vector__XXX
 SG_ CELL_4x5_isDischarging : 48|1@1+ (1,0) [0|0] "" Vector__XXX
 SG_ CELL_4x5_Temp : 32|16@1- (0.01,0) [0|0] "degC" Vector__XXX
 SG_ CELL_4x5_VoltageDiff : 16|16@1- (1,0) [0|0] "mV" Vector__XXX
 SG_ CELL_4x5_Voltage : 0|16@1- (0.001,0) [0|0] "V" Vector__XXX

BO_ 2147528757 CELL_4x6_MSG: 8 BMS
 SG_ CELL_4x6_isFaultDetected : 49|1@1+ (1,0) [0|0] "" Vector__XXX
 SG_ CELL_4x6_isDischarging : 48|1@1+ (1,0) [0|0] "" Vector__XXX
 SG_ CELL_4x6_Temp : 32|16@1- (0.01,0) [0|0] "degC" Vector__XXX
 SG_ CELL_4x6_VoltageDiff : 16|16@1- (1,0) [0|0] "mV" Vector__XXX
 SG_ CELL_4x6_Voltage : 0|16@1- (0.001,0) [0|0] "V" Vector__XXX

BO_ 2147528758 CELL_4x7_MSG: 8 BMS
 SG_ CELL_4x7_isFaultDetected : 49|1@1+ (1,0) [0|0] "" Vector__XXX
 SG_ CELL_4x7_isDischarging : 48|1@1+ (1,0) [0|0] "" Vector__XXX
 SG_ CELL_4x7_Temp : 32|16@1- (0.01,0) [0|0] "degC" Vector__XXX
 SG_ CELL_4x7_VoltageDiff : 16|16@1- (1,0) [0|0] "mV" Vector__XXX
 SG_ CELL_4x7_Voltage : 0|16@1- (0.001,0) [0|0] "V" Vector__XXX

BO_ 2147528759 CELL_4x8_MSG: 8 BMS
 SG_ CELL_4x8_isFaultDetected : 49|1@1+ (1,0) [0|0] "" Vector__XXX
 SG_ CELL_4x8_isDischarging : 48|1@1+ (1,0) [0|0] "" Vector__XXX
 SG_ CELL_4x8_Temp : 32|16@1- (0.01,0) [0|0] "degC" Vector__XXX
 SG_ CELL_4x8_VoltageDiff : 16|16@1- (1,0) [0|0] "mV" Vector__XXX
 SG_ CELL_4x8_Voltage : 0|16@1- (0.001,0) [0|0] "V" Vector__XXX

BO_ 2147528760 CELL_4x9_MSG: 8 BMS
 SG_ CELL_4x9_isFaultDetected : 49|1@1+ (1,0) [0|0] "" Vector__XXX
 SG_ CELL_4x9_isDischarging : 48|1@1+ (1,0) [0|0] "" Vector__XXX
 SG_ CELL_4x9_Temp : 32|16@1- (0.01,0) [0|0] "degC" Vector__XXX
 SG_ CELL_4x9_VoltageDiff : 16|16@1- (1,0) [0|0] "mV" Vector__XXX
 SG_ CELL_4x9_Voltage : 0|16@1- (0.001,0) [0|0] "V" Vector__XXX

BO_ 2147528761 CELL_4x10_MSG: 8 BMS
 SG_ CELL_4x10_isFaultDetected : 49|1@1+ (1,0) [0|0] "" Vector__XXX
 SG_ CELL_4x10_isDischarging : 48|1@1+ (1,0) [0|0] "" Vector__XXX
 SG_ CELL_4x10_Temp : 32|16@1- (0.01,0) [0|0] "degC" Vector__XXX
 SG_ CELL_4x10_VoltageDiff : 16|16@1- (1,0) [0|0] "mV" Vector__XXX
 SG_ CELL_4x10_Voltage : 0|16@1- (0.001,0) [0|0] "V" Vector__XXX

BO_ 2147528762 CELL_4x11_MSG: 8 BMS
 SG_ CELL_4x11_isFaultDetected : 49|1@1+ (1,0) [0|0] "" Vector__XXX
 SG_ CELL_4x11_isDischarging : 48|1@1+ (1,0) [0|0] "" Vector__XXX
 SG_ CELL_4x11_Temp : 32|16@1- (0.01,0) [0|0] "degC" Vector__XXX
 SG_ CELL_4x11_VoltageDiff : 16|16@1- (1,0) [0|0] "mV" Vector__XXX
 SG_ CELL_4x11_Voltage : 0|16@1- (0.001,0) [0|0] "V" Vector__XXX

BO_ 2147528763 CELL_4x12_MSG: 8 BMS
 SG_ CELL_4x12_isFaultDetected : 49|1@1+ (1,0) [0|0] "" Vector__XXX
 SG_ CELL_4x12_isDischarging : 48|1@1+ (1,0) [0|0] "" Vector__XXX
 SG_ CELL_4x12_Temp : 32|16@1- (0.01,0) [0|0] "degC" Vector__XXX
 SG_ CELL_4x12_VoltageDiff : 16|16@1- (1,0) [0|0] "mV" Vector__XXX
 SG_ CELL_4x12_Voltage : 0|16@1- (0.001,0) [0|0] "V" Vector__XXX

BO_ 2147528764 CELL_4x13_MSG: 8 BMS
 SG_ CELL_4x13_isFaultDetected : 49|1@1+ (1,0) [0|0] "" Vector__XXX
 SG_ CELL_4x13_isDischarging : 48|1@1+ (1,0) [0|0] "" Vector__XXX
 SG_ CELL_4x13_Temp : 32|16@1- (0.01,0) [0|0] "degC" Vector__XXX
 SG_ CELL_4x13_VoltageDiff : 16|16@1- (1,0) [0|0] "mV" Vector__XXX
 SG_ CELL_4x13_Voltage : 0|16@1- (0.001,0) [0|0] "V" Vector__XXX

BO_ 2147528765 CELL_4x14_MSG: 8 BMS
 SG_ CELL_4x14_isFaultDetected : 49|1@1+ (1,0) [0|0] "" Vector__XXX
 SG_ CELL_4x14_isDischarging : 48|1@1+ (1,0) [0|0] "" Vector__XXX
 SG_ CELL_4x14_Temp : 32|16@1- (0.01,0) [0|0] "degC" Vector__XXX
 SG_ CELL_4x14_VoltageDiff : 16|16@1- (1,0) [0|0] "mV" Vector__XXX
 SG_ CELL_4x14_Voltage : 0|16@1- (0.001,0) [0|0] "V" Vector__XXX

BO_ 2147528766 CELL_4x15_MSG: 8 BMS
 SG_ CELL_4x15_isFaultDetected : 49|1@1+ (1,0) [0|0] "" Vector__XXX
 SG_ CELL_4x15_isDischarging : 48|1@1+ (1,0) [0|0] "" Vector__XXX
 SG_ CELL_4x15_Temp : 32|16@1- (0.01,0) [0|0] "degC" Vector__XXX
 SG_ CELL_4x15_VoltageDiff : 16|16@1- (1,0) [0|0] "mV" Vector__XXX
 SG_ CELL_4x15_Voltage : 0|16@1- (0.001,0) [0|0] "V" Vector__XXX

BO_ 2147528767 CELL_4x16_MSG: 8 BMS
 SG_ CELL_4x16_isFaultDetected : 49|1@1+ (1,0) [0|0] "" Vector__XXX
 SG_ CELL_4x16_isDischarging : 48|1@1+ (1,0) [0|0] "" Vector__XXX
 SG_ CELL_4x16_Temp : 32|16@1- (0.01,0) [0|0] "degC" Vector__XXX
 SG_ CELL_4x16_VoltageDiff : 16|16@1- (1,0) [0|0] "mV" Vector__XXX
 SG_ CELL_4x16_Voltage : 0|16@1- (0.001,0) [0|0] "V" Vector__XXX

BO_ 2147528820 SEG_5_MSG: 8 BMS
 SG_ SEG_5_isFaultDetected : 49|1@1+ (1,0) [0|0] "" Vector__XXX
 SG_ SEG_5_isCommsError : 48|1@1+ (1,0) [0|0] "" Vector__XXX
 SG_ SEG_5_IC_Temp : 32|16@1- (0.01,0) [0|0] "degC" Vector__XXX
 SG_ SEG_5_IC_Voltage : 0|32@1- (0.001,0) [0|0] "V" Vector__XXX

BO_ 2147528768 CELL_5x1_MSG: 8 BMS
 SG_ CELL_5x1_isFaultDetected : 49|1@1+ (1,0) [0|0] "" Vector__XXX
 SG_ CELL_5x1_isDischarging : 48|1@1+ (1,0) [0|0] "" Vector__XXX
 SG_ CELL_5x1_Temp : 32|16@1- (0.01,0) [0|0] "degC" Vector__XXX
 SG_ CELL_5x1_VoltageDiff : 16|16@1- (1,0) [0|0] "mV" Vector__XXX
 SG_ CELL_5x1_Voltage : 0|16@1- (0.001,0) [0|0] "V" Vector__XXX

BO_ 2147528769 CELL_5x2_MSG: 8 BMS
 SG_ CELL_5x2_isFaultDetected : 49|1@1+ (1,0) [0|0] "" Vector__XXX
 SG_ CELL_5x2_isDischarging : 48|1@1+ (1,0) [0|0] "" Vector__XXX
 SG_ CELL_5x2_Temp : 32|16@1- (0.01,0) [0|0] "degC" Vector__XXX
 SG_ CELL_5x2_VoltageDiff : 16|16@1- (1,0) [0|0] "mV" Vector__XXX
 SG_ CELL_5x2_Voltage : 0|16@1- (0.001,0) [0|0] "V" Vector__XXX

BO_ 2147528770 CELL_5x3_MSG: 8 BMS
 SG_ CELL_5x3_isFaultDetected : 49|1@1+ (1,0) [0|0] "" Vector__XXX
 SG_ CELL_5x3_isDischarging : 48|1@1+ (1,0) [0|0] "" Vector__XXX
 SG_ CELL_5x3_Temp : 32|16@1- (0.01,0) [0|0] "degC" Vector__XXX
 SG_ CELL_5x3_VoltageDiff : 16|16@1- (1,0) [0|0] "mV" Vector__XXX
 SG_ CELL_5x3_Voltage : 0|16@1- (0.001,0) [0|0] "V" Vector__XXX

BO_ 2147528771 CELL_5x4_MSG: 8 BMS
 SG_ CELL_5x4_isFaultDetected : 49|1@1+ (1,0) [0|0] "" Vector__XXX
 SG_ CELL_5x4_isDischarging : 48|1@1+ (1,0) [0|0] "" Vector__XXX
 SG_ CELL_5x4_Temp : 32|16@1- (0.01,0) [0|0] "degC" Vector__XXX
 SG_ CELL_5x4_VoltageDiff : 16|16@1- (1,0) [0|0] "mV" Vector__XXX
 SG_ CELL_5x4_Voltage : 0|16@1- (0.001,0) [0|0] "V" Vector__XXX

BO_ 2147528772 CELL_5x5_MSG: 8 BMS
 SG_ CELL_5x5_isFaultDetected : 49|1@1+ (1,0) [0|0] "" Vector__XXX
 SG_ CELL_5x5_isDischarging : 48|1@1+ (1,0) [0|0] "" Vector__XXX
 SG_ CELL_5x5_Temp : 32|16@1- (0.01,0) [0|0] "degC" Vector__XXX
 SG_ CELL_5x5_VoltageDiff : 16|16@1- (1,0) [0|0] "mV" Vector__XXX
 SG_ CELL_5x5_Voltage : 0|16@1- (0.001,0) [0|0] "V" Vector__XXX

BO_ 2147528773 CELL_5x6_MSG: 8 BMS
 SG_ CELL_5x6_isFaultDetected : 49|1@1+ (1,0) [0|0] "" Vector__XXX
 SG_ CELL_5x6_isDischarging : 48|1@1+ (1,0) [0|0] "" Vector__XXX
 SG_ CELL_5x6_Temp : 32|16@1- (0.01,0) [0|0] "degC" Vector__XXX
 SG_ CELL_5x6_VoltageDiff : 16|16@1- (1,0) [0|0] "mV" Vector__XXX
 SG_ CELL_5x6_Voltage : 0|16@1- (0.001,0) [0|0] "V" Vector__XXX

BO_ 2147528774 CELL_5x7_MSG: 8 BMS
 SG_ CELL_5x7_isFaultDetected : 49|1@1+ (1,0) [0|0] "" Vector__XXX
 SG_ CELL_5x7_isDischarging : 48|1@1+ (1,0) [0|0] "" Vector__XXX
 SG_ CELL_5x7_Temp : 32|16@1- (0.01,0) [0|0] "degC" Vector__XXX
 SG_ CELL_5x7_VoltageDiff : 16|16@1- (1,0) [0|0] "mV" Vector__XXX
 SG_ CELL_5x7_Voltage : 0|16@1- (0.001,0) [0|0] "V" Vector__XXX

BO_ 2147528775 CELL_5x8_MSG: 8 BMS
 SG_ CELL_5x8_isFaultDetected : 49|1@1+ (1,0) [0|0] "" Vector__XXX
 SG_ CELL_5x8_isDischarging : 48|1@1+ (1,0) [0|0] "" Vector__XXX
 SG_ CELL_5x8_Temp : 32|16@1- (0.01,0) [0|0] "degC" Vector__XXX
 SG_ CELL_5x8_VoltageDiff : 16|16@1- (1,0) [0|0] "mV" Vector__XXX
 SG_ CELL_5x8_Voltage : 0|16@1- (0.001,0) [0|0] "V" Vector__XXX

BO_ 2147528776 CELL_5x9_MSG: 8 BMS
 SG_ CELL_5x9_isFaultDetected : 49|1@1+ (1,0) [0|0] "" Vector__XXX
 SG_ CELL_5x9_isDischarging : 48|1@1+ (1,0) [0|0] "" Vector__XXX
 SG_ CELL_5x9_Temp : 32|16@1- (0.01,0) [0|0] "degC" Vector__XXX
 SG_ CELL_5x9_VoltageDiff : 16|16@1- (1,0) [0|0] "mV" Vector__XXX
 SG_ CELL_5x9_Voltage : 0|16@1- (0.001,0) [0|0] "V" Vector__XXX

BO_ 2147528777 CELL_5x10_MSG: 8 BMS
 SG_ CELL_5x10_isFaultDetected : 49|1@1+ (1,0) [0|0] "" Vector__XXX
 SG_ CELL_5x10_isDischarging : 48|1@1+ (1,0) [0|0] "" Vector__XXX
 SG_ CELL_5x10_Temp : 32|16@1- (0.01,0) [0|0] "degC" Vector__XXX
 SG_ CELL_5x10_VoltageDiff : 16|16@1- (1,0) [0|0] "mV" Vector__XXX
 SG_ CELL_5x10_Voltage : 0|16@1- (0.001,0) [0|0] "V" Vector__XXX

BO_ 2147528778 CELL_5x11_MSG: 8 BMS
 SG_ CELL_5x11_isFaultDetected : 49|1@1+ (1,0) [0|0] "" Vector__XXX
 SG_ CELL_5x11_isDischarging : 48|1@1+ (1,0) [0|0] "" Vector__XXX
 SG_ CELL_5x11_Temp : 32|16@1- (0.01,0) [0|0] "degC" Vector__XXX
 SG_ CELL_5x11_VoltageDiff : 16|16@1- (1,0) [0|0] "mV" Vector__XXX
 SG_ CELL_5x11_Voltage : 0|16@1- (0.001,0) [0|0] "V" Vector__XXX

BO_ 2147528779 CELL_5x12_MSG: 8 BMS
 SG_ CELL_5x12_isFaultDetected : 49|1@1+ (1,0) [0|0] "" Vector__XXX
 SG_ CELL_5x12_isDischarging : 48|1@1+ (1,0) [0|0] "" Vector__XXX
 SG_ CELL_5x12_Temp : 32|16@1- (0.01,0) [0|0] "degC" Vector__XXX
 SG_ CELL_5x12_VoltageDiff : 16|16@1- (1,0) [0|0] "mV" Vector__XXX
 SG_ CELL_5x12_Voltage : 0|16@1- (0.001,0) [0|0] "V" Vector__XXX

BO_ 2147528780 CELL_5x13_MSG: 8 BMS
 SG_ CELL_5x13_isFaultDetected : 49|1@1+ (1,0) [0|0] "" Vector__XXX
 SG_ CELL_5x13_isDischarging : 48|1@1+ (1,0) [0|0] "" Vector__XXX
 SG_ CELL_5x13_Temp : 32|16@1- (0.01,0) [0|0] "degC" Vector__XXX
 SG_ CELL_5x13_VoltageDiff : 16|16@1- (1,0) [0|0] "mV" Vector__XXX
 SG_ CELL_5x13_Voltage : 0|16@1- (0.001,0) [0|0] "V" Vector__XXX

BO_ 2147528781 CELL_5x14_MSG: 8 BMS
 SG_ CELL_5x14_isFaultDetected : 49|1@1+ (1,0) [0|0] "" Vector__XXX
 SG_ CELL_5x14_isDischarging : 48|1@1+ (1,0) [0|0] "" Vector__XXX
 SG_ CELL_5x14_Temp : 32|16@1- (0.01,0) [0|0] "degC" Vector__XXX
 SG_ CELL_5x14_VoltageDiff : 16|16@1- (1,0) [0|0] "mV" Vector__XXX
 SG_ CELL_5x14_Voltage : 0|16@1- (0.001,0) [0|0] "V" Vector__XXX

BO_ 2147528782 CELL_5x15_MSG: 8 BMS
 SG_ CELL_5x15_isFaultDetected : 49|1@1+ (1,0) [0|0] "" Vector__XXX
 SG_ CELL_5x15_isDischarging : 48|1@1+ (1,0) [0|0] "" Vector__XXX
 SG_ CELL_5x15_Temp : 32|16@1- (0.01,0) [0|0] "degC" Vector__XXX
 SG_ CELL_5x15_VoltageDiff : 16|16@1- (1,0) [0|0] "mV" Vector__XXX
 SG_ CELL_5x15_Voltage : 0|16@1- (0.001,0) [0|0] "V" Vector__XXX

BO_ 2147528783 CELL_5x16_MSG: 8 BMS
 SG_ CELL_5x16_isFaultDetected : 49|1@1+ (1,0) [0|0] "" Vector__XXX
 SG_ CELL_5x16_isDischarging : 48|1@1+ (1,0) [0|0] "" Vector__XXX
 SG_ CELL_5x16_Temp : 32|16@1- (0.01,0) [0|0] "degC" Vector__XXX
 SG_ CELL_5x16_VoltageDiff : 16|16@1- (1,0) [0|0] "mV" Vector__XXX
 SG_ CELL_5x16_Voltage : 0|16@1- (0.001,0) [0|0] "V" Vector__XXX

BO_ 2147528821 SEG_6_MSG: 8 BMS
 SG_ SEG_6_isFaultDetected : 49|1@1+ (1,0) [0|0] "" Vector__XXX
 SG_ SEG_6_isCommsError : 48|1@1+ (1,0) [0|0] "" Vector__XXX
 SG_ SEG_6_IC_Temp : 32|16@1- (0.01,0) [0|0] "degC" Vector__XXX
 SG_ SEG_6_IC_Voltage : 0|32@1- (0.001,0) [0|0] "V" Vector__XXX

BO_ 2147528784 CELL_6x1_MSG: 8 BMS
 SG_ CELL_6x1_isFaultDetected : 49|1@1+ (1,0) [0|0] "" Vector__XXX
 SG_ CELL_6x1_isDischarging : 48|1@1+ (1,0) [0|0] "" Vector__XXX
 SG_ CELL_6x1_Temp : 32|16@1- (0.01,0) [0|0] "degC" Vector__XXX
 SG_ CELL_6x1_VoltageDiff : 16|16@1- (1,0) [0|0] "mV" Vector__XXX
 SG_ CELL_6x1_Voltage : 0|16@1- (0.001,0) [0|0] "V" Vector__XXX

BO_ 2147528785 CELL_6x2_MSG: 8 BMS
 SG_ CELL_6x2_isFaultDetected : 49|1@1+ (1,0) [0|0] "" Vector__XXX
 SG_ CELL_6x2_isDischarging : 48|1@1+ (1,0) [0|0] "" Vector__XXX
 SG_ CELL_6x2_Temp : 32|16@1- (0.01,0) [0|0] "degC" Vector__XXX
 SG_ CELL_6x2_VoltageDiff : 16|16@1- (1,0) [0|0] "mV" Vector__XXX
 SG_ CELL_6x2_Voltage : 0|16@1- (0.001,0) [0|0] "V" Vector__XXX

BO_ 2147528786 CELL_6x3_MSG: 8 BMS
 SG_ CELL_6x3_isFaultDetected : 49|1@1+ (1,0) [0|0] "" Vector__XXX
 SG_ CELL_6x3_isDischarging : 48|1@1+ (1,0) [0|0] "" Vector__XXX
 SG_ CELL_6x3_Temp : 32|16@1- (0.01,0) [0|0] "degC" Vector__XXX
 SG_ CELL_6x3_VoltageDiff : 16|16@1- (1,0) [0|0] "mV" Vector__XXX
 SG_ CELL_6x3_Voltage : 0|16@1- (0.001,0) [0|0] "V" Vector__XXX

BO_ 2147528787 CELL_6x4_MSG: 8 BMS
 SG_ CELL_6x4_isFaultDetected : 49|1@1+ (1,0) [0|0] "" Vector__XXX
 SG_ CELL_6x4_isDischarging : 48|1@1+ (1,0) [0|0] "" Vector__XXX
 SG_ CELL_6x4_Temp : 32|16@1- (0.01,0) [0|0] "degC" Vector__XXX
 SG_ CELL_6x4_VoltageDiff : 16|16@1- (1,0) [0|0] "mV" Vector__XXX
 SG_ CELL_6x4_Voltage : 0|16@1- (0.001,0) [0|0] "V" Vector__XXX

BO_ 2147528788 CELL_6x5_MSG: 8 BMS
 SG_ CELL_6x5_isFaultDetected : 49|1@1+ (1,0) [0|0] "" Vector__XXX
 SG_ CELL_6x5_isDischarging : 48|1@1+ (1,0) [0|0] "" Vector__XXX
 SG_ CELL_6x5_Temp : 32|16@1- (0.01,0) [0|0] "degC" Vector__XXX
 SG_ CELL_6x5_VoltageDiff : 16|16@1- (1,0) [0|0] "mV" Vector__XXX
 SG_ CELL_6x5_Voltage : 0|16@1- (0.001,0) [0|0] "V" Vector__XXX

BO_ 2147528789 CELL_6x6_MSG: 8 BMS
 SG_ CELL_6x6_isFaultDetected : 49|1@1+ (1,0) [0|0] "" Vector__XXX
 SG_ CELL_6x6_isDischarging : 48|1@1+ (1,0) [0|0] "" Vector__XXX
 SG_ CELL_6x6_Temp : 32|16@1- (0.01,0) [0|0] "degC" Vector__XXX
 SG_ CELL_6x6_VoltageDiff : 16|16@1- (1,0) [0|0] "mV" Vector__XXX
 SG_ CELL_6x6_Voltage : 0|16@1- (0.001,0) [0|0] "V" Vector__XXX

BO_ 2147528790 CELL_6x7_MSG: 8 BMS
 SG_ CELL_6x7_isFaultDetected : 49|1@1+ (1,0) [0|0] "" Vector__XXX
 SG_ CELL_6x7_isDischarging : 48|1@1+ (1,0) [0|0] "" Vector__XXX
 SG_ CELL_6x7_Temp : 32|16@1- (0.01,0) [0|0] "degC" Vector__XXX
 SG_ CELL_6x7_VoltageDiff : 16|16@1- (1,0) [0|0] "mV" Vector__XXX
 SG_ CELL_6x7_Voltage : 0|16@1- (0.001,0) [0|0] "V" Vector__XXX

BO_ 2147528791 CELL_6x8_MSG: 8 BMS
 SG_ CELL_6x8_isFaultDetected : 49|1@1+ (1,0) [0|0] "" Vector__XXX
 SG_ CELL_6x8_isDischarging : 48|1@1+ (1,0) [0|0] "" Vector__XXX
 SG_ CELL_6x8_Temp : 32|16@1- (0.01,0) [0|0] "degC" Vector__XXX
 SG_ CELL_6x8_VoltageDiff : 16|16@1- (1,0) [0|0] "mV" Vector__XXX
 SG_ CELL_6x8_Voltage : 0|16@1- (0.001,0) [0|0] "V" Vector__XXX

BO_ 2147528792 CELL_6x9_MSG: 8 BMS
 SG_ CELL_6x9_isFaultDetected : 49|1@1+ (1,0) [0|0] "" Vector__XXX
 SG_ CELL_6x9_isDischarging : 48|1@1+ (1,0) [0|0] "" Vector__XXX
 SG_ CELL_6x9_Temp : 32|16@1- (0.01,0) [0|0] "degC" Vector__XXX
 SG_ CELL_6x9_VoltageDiff : 16|16@1- (1,0) [0|0] "mV" Vector__XXX
 SG_ CELL_6x9_Voltage : 0|16@1- (0.001,0) [0|0] "V" Vector__XXX

BO_ 2147528793 CELL_6x10_MSG: 8 BMS
 SG_ CELL_6x10_isFaultDetected : 49|1@1+ (1,0) [0|0] "" Vector__XXX
 SG_ CELL_6x10_isDischarging : 48|1@1+ (1,0) [0|0] "" Vector__XXX
 SG_ CELL_6x10_Temp : 32|16@1- (0.01,0) [0|0] "degC" Vector__XXX
 SG_ CELL_6x10_VoltageDiff : 16|16@1- (1,0) [0|0] "mV" Vector__XXX
 SG_ CELL_6x10_Voltage : 0|16@1- (0.001,0) [0|0] "V" Vector__XXX

BO_ 2147528794 CELL_6x11_MSG: 8 BMS
 SG_ CELL_6x11_isFaultDetected : 49|1@1+ (1,0) [0|0] "" Vector__XXX
 SG_ CELL_6x11_isDischarging : 48|1@1+ (1,0) [0|0] "" Vector__XXX
 SG_ CELL_6x11_Temp : 32|16@1- (0.01,0) [0|0] "degC" Vector__XXX
 SG_ CELL_6x11_VoltageDiff : 16|16@1- (1,0) [0|0] "mV" Vector__XXX
 SG_ CELL_6x11_Voltage : 0|16@1- (0.001,0) [0|0] "V" Vector__XXX

BO_ 2147528795 CELL_6x12_MSG: 8 BMS
 SG_ CELL_6x12_isFaultDetected : 49|1@1+ (1,0) [0|0] "" Vector__XXX
 SG_ CELL_6x12_isDischarging : 48|1@1+ (1,0) [0|0] "" Vector__XXX
 SG_ CELL_6x12_Temp : 32|16@1- (0.01,0) [0|0] "degC" Vector__XXX
 SG_ CELL_6x12_VoltageDiff : 16|16@1- (1,0) [0|0] "mV" Vector__XXX
 SG_ CELL_6x12_Voltage : 0|16@1- (0.001,0) [0|0] "V" Vector__XXX

BO_ 2147528796 CELL_6x13_MSG: 8 BMS
 SG_ CELL_6x13_isFaultDetected : 49|1@1+ (1,0) [0|0] "" Vector__XXX
 SG_ CELL_6x13_isDischarging : 48|1@1+ (1,0) [0|0] "" Vector__XXX
 SG_ CELL_6x13_Temp : 32|16@1- (0.01,0) [0|0] "degC" Vector__XXX
 SG_ CELL_6x13_VoltageDiff : 16|16@1- (1,0) [0|0] "mV" Vector__XXX
 SG_ CELL_6x13_Voltage : 0|16@1- (0.001,0) [0|0] "V" Vector__XXX

BO_ 2147528797 CELL_6x14_MSG: 8 BMS
 SG_ CELL_6x14_isFaultDetected : 49|1@1+ (1,0) [0|0] "" Vector__XXX
 SG_ CELL_6x14_isDischarging : 48|1@1+ (1,0) [0|0] "" Vector__XXX
 SG_ CELL_6x14_Temp : 32|16@1- (0.01,0) [0|0] "degC" Vector__XXX
 SG_ CELL_6x14_VoltageDiff : 16|16@1- (1,0) [0|0] "mV" Vector__XXX
 SG_ CELL_6x14_Voltage : 0|16@1- (0.001,0) [0|0] "V" Vector__XXX

BO_ 2147528798 CELL_6x15_MSG: 8 BMS
 SG_ CELL_6x15_isFaultDetected : 49|1@1+ (1,0) [0|0] "" Vector__XXX
 SG_ CELL_6x15_isDischarging : 48|1@1+ (1,0) [0|0] "" Vector__XXX
 SG_ CELL_6x15_Temp : 32|16@1- (0.01,0) [0|0] "degC" Vector__XXX
 SG_ CELL_6x15_VoltageDiff : 16|16@1- (1,0) [0|0] "mV" Vector__XXX
 SG_ CELL_6x15_Voltage : 0|16@1- (0.001,0) [0|0] "V" Vector__XXX

BO_ 2147528799 CELL_6x16_MSG: 8 BMS
 SG_ CELL_6x16_isFaultDetected : 49|1@1+ (1,0) [0|0] "" Vector__XXX
 SG_ CELL_6x16_isDischarging : 48|1@1+ (1,0) [0|0] "" Vector__XXX
 SG_ CELL_6x16_Temp : 32|16@1- (0.01,0) [0|0] "degC" Vector__XXX
 SG_ CELL_6x16_VoltageDiff : 16|16@1- (1,0) [0|0] "mV" Vector__XXX
 SG_ CELL_6x16_Voltage : 0|16@1- (0.001,0) [0|0] "V" Vector__XXX

BO_ 2147528822 SEG_7_MSG: 8 BMS
 SG_ SEG_7_isFaultDetected : 49|1@1+ (1,0) [0|0] "" Vector__XXX
 SG_ SEG_7_isCommsError : 48|1@1+ (1,0) [0|0] "" Vector__XXX
 SG_ SEG_7_IC_Temp : 32|16@1- (0.01,0) [0|0] "degC" Vector__XXX
 SG_ SEG_7_IC_Voltage : 0|32@1- (0.001,0) [0|0] "V" Vector__XXX

BO_ 2147528800 CELL_7x1_MSG: 8 BMS
 SG_ CELL_7x1_isFaultDetected : 49|1@1+ (1,0) [0|0] "" Vector__XXX
 SG_ CELL_7x1_isDischarging : 48|1@1+ (1,0) [0|0] "" Vector__XXX
 SG_ CELL_7x1_Temp : 32|16@1- (0.01,0) [0|0] "degC" Vector__XXX
 SG_ CELL_7x1_VoltageDiff : 16|16@1- (1,0) [0|0] "mV" Vector__XXX
 SG_ CELL_7x1_Voltage : 0|16@1- (0.001,0) [0|0] "V" Vector__XXX

BO_ 2147528801 CELL_7x2_MSG: 8 BMS
 SG_ CELL_7x2_isFaultDetected : 49|1@1+ (1,0) [0|0] "" Vector__XXX
 SG_ CELL_7x2_isDischarging : 48|1@1+ (1,0) [0|0] "" Vector__XXX
 SG_ CELL_7x2_Temp : 32|16@1- (0.01,0) [0|0] "degC" Vector__XXX
 SG_ CELL_7x2_VoltageDiff : 16|16@1- (1,0) [0|0] "mV" Vector__XXX
 SG_ CELL_7x2_Voltage : 0|16@1- (0.001,0) [0|0] "V" Vector__XXX

BO_ 2147528802 CELL_7x3_MSG: 8 BMS
 SG_ CELL_7x3_isFaultDetected : 49|1@1+ (1,0) [0|0] "" Vector__XXX
 SG_ CELL_7x3_isDischarging : 48|1@1+ (1,0) [0|0] "" Vector__XXX
 SG_ CELL_7x3_Temp : 32|16@1- (0.01,0) [0|0] "degC" Vector__XXX
 SG_ CELL_7x3_VoltageDiff : 16|16@1- (1,0) [0|0] "mV" Vector__XXX
 SG_ CELL_7x3_Voltage : 0|16@1- (0.001,0) [0|0] "V" Vector__XXX

BO_ 2147528803 CELL_7x4_MSG: 8 BMS
 SG_ CELL_7x4_isFaultDetected : 49|1@1+ (1,0) [0|0] "" Vector__XXX
 SG_ CELL_7x4_isDischarging : 48|1@1+ (1,0) [0|0] "" Vector__XXX
 SG_ CELL_7x4_Temp : 32|16@1- (0.01,0) [0|0] "degC" Vector__XXX
 SG_ CELL_7x4_VoltageDiff : 16|16@1- (1,0) [0|0] "mV" Vector__XXX
 SG_ CELL_7x4_Voltage : 0|16@1- (0.001,0) [0|0] "V" Vector__XXX

BO_ 2147528804 CELL_7x5_MSG: 8 BMS
 SG_ CELL_7x5_isFaultDetected : 49|1@1+ (1,0) [0|0] "" Vector__XXX
 SG_ CELL_7x5_isDischarging : 48|1@1+ (1,0) [0|0] "" Vector__XXX
 SG_ CELL_7x5_Temp : 32|16@1- (0.01,0) [0|0] "degC" Vector__XXX
 SG_ CELL_7x5_VoltageDiff : 16|16@1- (1,0) [0|0] "mV" Vector__XXX
 SG_ CELL_7x5_Voltage : 0|16@1- (0.001,0) [0|0] "V" Vector__XXX

BO_ 2147528805 CELL_7x6_MSG: 8 BMS
 SG_ CELL_7x6_isFaultDetected : 49|1@1+ (1,0) [0|0] "" Vector__XXX
 SG_ CELL_7x6_isDischarging : 48|1@1+ (1,0) [0|0] "" Vector__XXX
 SG_ CELL_7x6_Temp : 32|16@1- (0.01,0) [0|0] "degC" Vector__XXX
 SG_ CELL_7x6_VoltageDiff : 16|16@1- (1,0) [0|0] "mV" Vector__XXX
 SG_ CELL_7x6_Voltage : 0|16@1- (0.001,0) [0|0] "V" Vector__XXX

BO_ 2147528806 CELL_7x7_MSG: 8 BMS
 SG_ CELL_7x7_isFaultDetected : 49|1@1+ (1,0) [0|0] "" Vector__XXX
 SG_ CELL_7x7_isDischarging : 48|1@1+ (1,0) [0|0] "" Vector__XXX
 SG_ CELL_7x7_Temp : 32|16@1- (0.01,0) [0|0] "degC" Vector__XXX
 SG_ CELL_7x7_VoltageDiff : 16|16@1- (1,0) [0|0] "mV" Vector__XXX
 SG_ CELL_7x7_Voltage : 0|16@1- (0.001,0) [0|0] "V" Vector__XXX

BO_ 2147528807 CELL_7x8_MSG: 8 BMS
 SG_ CELL_7x8_isFaultDetected : 49|1@1+ (1,0) [0|0] "" Vector__XXX
 SG_ CELL_7x8_isDischarging : 48|1@1+ (1,0) [0|0] "" Vector__XXX
 SG_ CELL_7x8_Temp : 32|16@1- (0.01,0) [0|0] "degC" Vector__XXX
 SG_ CELL_7x8_VoltageDiff : 16|16@1- (1,0) [0|0] "mV" Vector__XXX
 SG_ CELL_7x8_Voltage : 0|16@1- (0.001,0) [0|0] "V" Vector__XXX

BO_ 2147528808 CELL_7x9_MSG: 8 BMS
 SG_ CELL_7x9_isFaultDetected : 49|1@1+ (1,0) [0|0] "" Vector__XXX
 SG_ CELL_7x9_isDischarging : 48|1@1+ (1,0) [0|0] "" Vector__XXX
 SG_ CELL_7x9_Temp : 32|16@1- (0.01,0) [0|0] "degC" Vector__XXX
 SG_ CELL_7x9_VoltageDiff : 16|16@1- (1,0) [0|0] "mV" Vector__XXX
 SG_ CELL_7x9_Voltage : 0|16@1- (0.001,0) [0|0] "V" Vector__XXX

BO_ 2147528809 CELL_7x10_MSG: 8 BMS
 SG_ CELL_7x10_isFaultDetected : 49|1@1+ (1,0) [0|0] "" Vector__XXX
 SG_ CELL_7x10_isDischarging : 48|1@1+ (1,0) [0|0] "" Vector__XXX
 SG_ CELL_7x10_Temp : 32|16@1- (0.01,0) [0|0] "degC" Vector__XXX
 SG_ CELL_7x10_VoltageDiff : 16|16@1- (1,0) [0|0] "mV" Vector__XXX
 SG_ CELL_7x10_Voltage : 0|16@1- (0.001,0) [0|0] "V" Vector__XXX

BO_ 2147528810 CELL_7x11_MSG: 8 BMS
 SG_ CELL_7x11_isFaultDetected : 49|1@1+ (1,0) [0|0] "" Vector__XXX
 SG_ CELL_7x11_isDischarging : 48|1@1+ (1,0) [0|0] "" Vector__XXX
 SG_ CELL_7x11_Temp : 32|16@1- (0.01,0) [0|0] "degC" Vector__XXX
 SG_ CELL_7x11_VoltageDiff : 16|16@1- (1,0) [0|0] "mV" Vector__XXX
 SG_ CELL_7x11_Voltage : 0|16@1- (0.001,0) [0|0] "V" Vector__XXX

BO_ 2147528811 CELL_7x12_MSG: 8 BMS
 SG_ CELL_7x12_isFaultDetected : 49|1@1+ (1,0) [0|0] "" Vector__XXX
 SG_ CELL_7x12_isDischarging : 48|1@1+ (1,0) [0|0] "" Vector__XXX
 SG_ CELL_7x12_Temp : 32|16@1- (0.01,0) [0|0] "degC" Vector__XXX
 SG_ CELL_7x12_VoltageDiff : 16|16@1- (1,0) [0|0] "mV" Vector__XXX
 SG_ CELL_7x12_Voltage : 0|16@1- (0.001,0) [0|0] "V" Vector__XXX

BO_ 2147528812 CELL_7x13_MSG: 8 BMS
 SG_ CELL_7x13_isFaultDetected : 49|1@1+ (1,0) [0|0] "" Vector__XXX
 SG_ CELL_7x13_isDischarging : 48|1@1+ (1,0) [0|0] "" Vector__XXX
 SG_ CELL_7x13_Temp : 32|16@1- (0.01,0) [0|0] "degC" Vector__XXX
 SG_ CELL_7x13_VoltageDiff : 16|16@1- (1,0) [0|0] "mV" Vector__XXX
 SG_ CELL_7x13_Voltage : 0|16@1- (0.001,0) [0|0] "V" Vector__XXX

BO_ 2147528813 CELL_7x14_MSG: 8 BMS
 SG_ CELL_7x14_isFaultDetected : 49|1@1+ (1,0) [0|0] "" Vector__XXX
 SG_ CELL_7x14_isDischarging : 48|1@1+ (1,0) [0|0] "" Vector__XXX
 SG_ CELL_7x14_Temp : 32|16@1- (0.01,0) [0|0] "degC" Vector__XXX
 SG_ CELL_7x14_VoltageDiff : 16|16@1- (1,0) [0|0] "mV" Vector__XXX
 SG_ CELL_7x14_Voltage : 0|16@1- (0.001,0) [0|0] "V" Vector__XXX

BO_ 2147528814 CELL_7x15_MSG: 8 BMS
 SG_ CELL_7x15_isFaultDetected : 49|1@1+ (1,0) [0|0] "" Vector__XXX
 SG_ CELL_7x15_isDischarging : 48|1@1+ (1,0) [0|0] "" Vector__XXX
 SG_ CELL_7x15_Temp : 32|16@1- (0.01,0) [0|0] "degC" Vector__XXX
 SG_ CELL_7x15_VoltageDiff : 16|16@1- (1,0) [0|0] "mV" Vector__XXX
 SG_ CELL_7x15_Voltage : 0|16@1- (0.001,0) [0|0] "V" Vector__XXX

BO_ 2147528815 CELL_7x16_MSG: 8 BMS
 SG_ CELL_7x16_isFaultDetected : 49|1@1+ (1,0) [0|0] "" Vector__XXX
 SG_ CELL_7x16_isDischarging : 48|1@1+ (1,0) [0|0] "" Vector__XXX
 SG_ CELL_7x16_Temp : 32|16@1- (0.01,0) [0|0] "degC" Vector__XXX
 SG_ CELL_7x16_VoltageDiff : 16|16@1- (1,0) [0|0] "mV" Vector__XXX
 SG_ CELL_7x16_Voltage : 0|16@1- (0.001,0) [0|0] "V" Vector__XXX

BO_ 2147528823 PACK_MSG: 8 BMS
 SG_ BMS_Pack_Current : 16|16@1- (0.01,0) [0|0] "A" Vector__XXX
 SG_ BMS_Pack_Voltage : 0|16@1- (0.1,0) [0|0] "V" Vector__XXX

BO_ 2147528824 PACK_STATUS_MSG: 8 BMS
 SG_ BMS_MSTR_isFaultDetected : 1|1@1+ (1,0) [0|0] "" Vector__XXX
 SG_ BMS_MSTR_isCommsError : 0|1@1+ (1,0) [0|0] "" Vector__XXX
